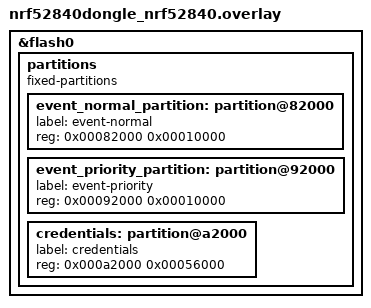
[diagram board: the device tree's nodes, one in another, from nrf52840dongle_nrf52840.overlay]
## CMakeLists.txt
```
cmake_minimum_required(VERSION 3.20.0)
find_package(Zephyr REQUIRED HINTS $ENV{ZEPHYR_BASE})
#set(ZEPHRY_MODULES modules/meta)

project(z9-lock)
include_directories(SYSTEM ../modules/meta/include)
include_directories(../z9-zephyr/ble)
target_sources(app PRIVATE src/main.cc)
target_sources(app PRIVATE src/button.c)

#target_sources(app PRIVATE ../z9-zephyr/ble/z9_ble_driver.c)
#target_sources(app PRIVATE ../z9-zephyr/ble/z9lockio_ble.cc)
target_sources(app PRIVATE ../z9-zephyr/ble/Z9Lock_status.cc)
target_sources(app PRIVATE ../z9-zephyr/ble/Eros_protocol.cc)
target_sources(app PRIVATE ../z9-zephyr/ble/Z9Crypto.cc)
target_sources(app PRIVATE ../z9-zephyr/ble/Z9Crypto_gcm_KCB.cc)
target_sources(app PRIVATE ../z9-zephyr/ble/EventDb.cc)
target_sources(app PRIVATE ../z9-zephyr/ble/Settings.cc)
target_sources(app PRIVATE ../z9-zephyr/ble/KernelBuffer.c)
target_sources(app PRIVATE ../z9-zephyr/ble/KernelCharacterBuffer.c)
target_sources(app PRIVATE ../z9-zephyr/ble/Z9LockIO_protocol.cc)
target_sources(app PRIVATE ../z9-zephyr/ble/Z9LockIO_bundleHeader.cc)
target_sources(app PRIVATE ../z9-zephyr/ble/Z9LockIO_opaqueContent.cc)
target_sources(app PRIVATE ../z9-zephyr/ble/Z9LockIO_eventControl.cc)
target_sources(app PRIVATE ../z9-zephyr/ble/Z9LockIO_keyExchange.cc)
target_sources(app PRIVATE ../z9-zephyr/ble/Z9LockIO_accessReq.cc)
target_sources(app PRIVATE ../z9-zephyr/ble/Z9LockIO_dbChange.cc)
target_sources(app PRIVATE ../z9-zephyr/ble/Z9LockIO_credAuthorization.cc)

#target_sources(app PRIVATE ../z9-zephyr/ble/DbStore.cc)
target_sources(app PRIVATE ../z9-zephyr/ble/Z9IO_Device.c)
target_sources(app PRIVATE ../z9-zephyr/ble/Z9IO_Link_Controller.cc)
# target_sources(app PRIVATE ../z9-zephyr/ble/Z9IO_Link_Remote.cc)
target_sources(app PRIVATE ../z9-zephyr/ble/ModelInfo.cc)
target_sources(app PRIVATE ../z9-zephyr/ble/Z9IO_Logic.cc)
# target_sources(app PRIVATE src/Z9Crypto.cc src/Z9Crypto_gcm_KCB.cc)
target_sources(app PRIVATE ../z9-zephyr/ble/Crc16.c)
```

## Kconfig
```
menu "Z9Lock"

config Z9_READER
    bool "Enable Reader"
    default n

config Z9_CONTROLLER
    bool "Enable Controller"
    default n
endmenu

menu "Zephyr Kernel"
source "Kconfig.zephyr"
endmenu
```

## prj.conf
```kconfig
CONFIG_CPP=y
CONFIG_STD_CPP20=y
CONFIG_LIB_CPLUSPLUS=y
CONFIG_REQUIRES_FULL_LIBCPP=y
CONFIG_EXCEPTIONS=y

CONFIG_KERNEL_BIN_NAME="z9-lock"

#CONFIG_COMPILER_SAVE_TEMPS=y
#CONFIG_COMPILER_OPT=""

CONFIG_Z9_READER=n
CONFIG_Z9_CONTROLLER=y

CONFIG_SERIAL=y
CONFIG_UART_INTERRUPT_DRIVEN=y

# configs from ECDH
# The Zephyr CMSIS emulation assumes that ticks are ms, currently
CONFIG_SYS_CLOCK_TICKS_PER_SEC=1000

#CONFIG_MAIN_STACK_SIZE=4096
#CONFIG_HEAP_MEM_POOL_SIZE=4096

CONFIG_MAIN_STACK_SIZE=4096
CONFIG_HEAP_MEM_POOL_SIZE=4096

# enable below for Zephyr BLE controller
#CONFIG_BT_LL_SW_SPLIT=y
#CONFIG_BT=y
#CONFIG_BT_PERIPHERAL=y
#CONFIG_BT_SMP=y
#CONFIG_BT_GATT_CLIENT=y


#CONFIG_BT_PERIPHERAL=y
#CONFIG_BT_DEVICE_NAME="Z9 Lock"
#CONFIG_BT_USER_PHY_UPDATE=y


CONFIG_HWINFO=y
#CONFIG_NCS_SAMPLES_DEFAULTS=y

CONFIG_LOG=n
CONFIG_LOG_BUFFER_SIZE=4096
#CONFIG_LOG_IMMEDIATE=y

# CONFIG_BT_LOG_LEVEL_DBG=n
#CONFIG_BT_DEBUG_MONITOR_UART=y
#CONFIG_UART_CONSOLE=n

# enable NVS
CONFIG_FLASH=y
CONFIG_FLASH_PAGE_LAYOUT=y
CONFIG_FCB_ALLOW_FIXED_ENDMARKER=y
CONFIG_FLASH_MAP=y
CONFIG_FCB=y
CONFIG_NVS=y
#CONFIG_NVS_LOG_LEVEL_DBG=y
CONFIG_MPU_ALLOW_FLASH_WRITE=y
CONFIG_SETTINGS=y

# Enable MBEDTLS (for Zephyr, not NFC)
CONFIG_MBEDTLS=y
CONFIG_MBEDTLS_BUILTIN=y
CONFIG_MBEDTLS_CFG_FILE="config-tls-generic.h"
CONFIG_MBEDTLS_ENTROPY_ENABLED=y
CONFIG_MBEDTLS_PSA_CRYPTO_C=y
CONFIG_MBEDTLS_ZEPHYR_ENTROPY=y
#CONFIG_MBEDTLS_HEAP_SIZE=8192
CONFIG_MBEDTLS_ECDH_C=y
CONFIG_MBEDTLS_ECP_C=y
CONFIG_MBEDTLS_ECP_DP_SECP256R1_ENABLED=y
CONFIG_MBEDTLS_HASH_SHA256_ENABLED=y
CONFIG_MBEDTLS_CIPHER_AES_ENABLED=y
CONFIG_MBEDTLS_AES_ROM_TABLES=y
CONFIG_MBEDTLS_CIPHER_GCM_ENABLED=y
CONFIG_MBEDTLS_MAC_MD5_ENABLED=y
CONFIG_MBEDTLS_MAC_SHA1_ENABLED=y
CONFIG_MBEDTLS_MAC_SHA256_ENABLED=y
CONFIG_MBEDTLS_SHA256_SMALLER=y
CONFIG_MBEDTLS_CTR_DRBG_ENABLED=y
CONFIG_MBEDTLS_CIPHER=y
CONFIG_MBEDTLS_MD=y
CONFIG_MBEDTLS_ENTROPY_ENABLED=y
CONFIG_MBEDTLS_PK_WRITE_C=y
CONFIG_MBEDTLS_PSA_CRYPTO_C=y
CONFIG_MBEDTLS_SSL_MAX_CONTENT_LEN=1500
CONFIG_MBEDTLS_INIT=y
CONFIG_MBEDTLS_ZEPHYR_ENTROPY=y

# added for ATMEL random
CONFIG_ENTROPY_GENERATOR=y
CONFIG_TEST_RANDOM_GENERATOR=y

# Enable nordic security backend and PSA APIs
# config for 52840DK
#CONFIG_PSA_CRYPTO_DRIVER_OBERON=y
#CONFIG_PSA_CRYPTO_DRIVER_CC3XX=n

#CONFIG_NRF_SECURITY=y
#CONFIG_MBEDTLS_PSA_CRYPTO_C=y

#CONFIG_MBEDTLS_ENABLE_HEAP=y

## configure PSA
#CONFIG_PSA_WANT_KEY_TYPE_ECC_KEY_PAIR=y
#CONFIG_PSA_WANT_ECC_SECP_R1_256=y
#CONFIG_PSA_WANT_ALG_ECDH=y
#CONFIG_PSA_WANT_ALG_SHA_256=y
#CONFIG_PSA_WANT_KEY_TYPE_AES=y
#CONFIG_PSA_WANT_AES_KEY_SIZE_128=y
#CONFIG_PSA_WANT_ALG_GCM=y

# For key generation
#CONFIG_PSA_WANT_GENERATE_RANDOM=y

# Enable the LBS service
#CONFIG_BT_LBS=y
#CONFIG_BT_LBS_POLL_BUTTON=y
#CONFIG_DK_LIBRARY=y

CONFIG_BT_GATT_CLIENT=y
CONFIG_BT_USER_DATA_LEN_UPDATE=y
CONFIG_BT_CTLR_DATA_LENGTH_MAX=251
CONFIG_BT_BUF_ACL_RX_SIZE=251
CONFIG_BT_BUF_ACL_TX_SIZE=251
CONFIG_BT_L2CAP_TX_MTU=420
#CONFIG_BT_HCI_ACL_FLOW_CONTROL=y
#CONFIG_BT_L2CAP_RX_MTU=420

CONFIG_SYSTEM_WORKQUEUE_STACK_SIZE=8192
```

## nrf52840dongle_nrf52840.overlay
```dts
// To get started, press Ctrl+Space (or Option+Esc) to bring up the completion menu and view the available nodes.

// You can also use the buttons in the sidebar to perform actions on nodes.
// Actions currently available include:

// * Enabling / disabling the node
// * Adding the bus to a bus
// * Removing the node
// * Connecting ADC channels

// For more help, browse the DeviceTree documentation at https://docs.zephyrproject.org/latest/guides/dts/index.html
// You can also visit the nRF DeviceTree extension documentation at https://nrfconnect.github.io/vscode-nrf-connect/devicetree/nrfdevicetree.html
/delete-node/ &slot1_partition;
&flash0 {

	partitions {
		compatible = "fixed-partitions";
		#address-cells = <1>;
		#size-cells = <1>;

		event_normal_partition: partition@82000 {
			label = "event-normal";
			reg = <0x00082000 0x00010000>;
		};
		event_priority_partition: partition@92000 {
			label = "event-priority";
			reg = <0x00092000 0x00010000>;
		};
		credentials: partition@a2000 {
			label = "credentials";
			reg = <0x000a2000 0x00056000>;
		};
    };
};
```

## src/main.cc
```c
#include "button.h"
#include "Z9Lock_status.h"
#include "EventDb.h"
#include "Settings.h"

#ifdef CONFIG_Z9_READER
#include "z9lockio_ble.h"
#endif

#include <zephyr/kernel.h>
#include <zephyr/logging/log.h>

#include <zephyr/sys/printk.h>
#include <zephyr/drivers/gpio.h>


LOG_MODULE_REGISTER(z9_ble, LOG_LEVEL_INF);
#define RUN_LED_BLINK_INTERVAL 1000

#define GREEN_LED_NODE  DT_ALIAS(led0)
#define RED_LED_NODE    DT_ALIAS(led1)
static const gpio_dt_spec green_led = GPIO_DT_SPEC_GET(GREEN_LED_NODE, gpios);
static const gpio_dt_spec red_led   = GPIO_DT_SPEC_GET(RED_LED_NODE  , gpios);

static void set_green_led(bool led)
{
        gpio_pin_set_dt(&green_led, led);
}
static void set_red_led(bool led)
{
        gpio_pin_set_dt(&red_led, led);
}
static int init_leds()
{
        int err;
        err = gpio_is_ready_dt(&green_led);
        if (err < 0) return err;
     	err = gpio_pin_configure_dt(&green_led, GPIO_OUTPUT_ACTIVE);
        if (err < 0) return err;
        err = gpio_is_ready_dt(&red_led);
        if (err < 0) return err;
     	err = gpio_pin_configure_dt(&red_led, GPIO_OUTPUT_ACTIVE);
        if (err < 0) return err;
        set_green_led(0);
        set_red_led(0);
        return 0;
}

static void pairing_expired(struct k_work *work)
{
        printk("%s: expired\n", __func__);
        z9lock_status.set_mode(LockStatusMode::CONSTRUCTION);
}

static void perform_reset(struct k_work *work)
{
        printk("%s: expired\n", __func__);
        nvm_settings_reset();           // clear flash
        __NVIC_SystemReset();
}

K_WORK_DELAYABLE_DEFINE(pairing_timer, pairing_expired);
K_WORK_DELAYABLE_DEFINE(reset_timer  , perform_reset);

bool privacy_state;
static void button_changed(button_evt evt)
{
        auto&& lock = z9lock_status;
                
        bool is_pressed = evt == BUTTON_EVT_PRESSED;
        printk("red: is_pressed: %d\n", is_pressed);

        if (is_pressed)
                k_work_schedule(&reset_timer, K_SECONDS(10));
        else 
        {
                k_work_cancel_delayable(&reset_timer);

                // if in paired, then it's the priv button
                if (lock.mode == LockStatusMode::NORMAL)
                {
                        privacy_state ^= 1; //bool(button_state & RED_BUTTON);
                        set_red_led(privacy_state);
                }
                else
                {
                        k_work_schedule(&pairing_timer, K_SECONDS(30));
                        lock.set_mode(LockStatusMode::PAIRING);
                }
        }

        auto lock_mode = static_cast<uint8_t>(lock.mode);
        printk("%s: MODE=%d, PRIV=%d\n", __func__, lock_mode, privacy_state);
}


int main()
{
        int err;

        printk("Starting Z9Lock BLE Test Fixture\n");
        psa_crypto_init();              // XXX
 

#ifdef CONFIG_Z9_READER 
        // start the Z9 BLE stack
        printk("Initializing Bluetooth\n");
        z9lock_ble_init();
#endif

#ifdef CONFIG_Z9_CONTROLLER
        // LEDs & buttons on READER
        err = init_leds();
        if (err) {
                printk("LEDs init failed (err %d)\n", err);
                return err;
        }

        err = button_init(button_changed);
        if (err) {
                printk("Button init failed (err %d)\n", err);
                return err;
        }
        
        nvm_settings_init();           // read settings: retrive keys & set mode

        // startup complete -- generate an event
        LockEventDb::instance().save(EVT(LockEvtCode_STARTUP));

        // if in construction or pairing mode, blink LED 
        uint8_t blink_status = 0;
        for (;;)
        {
                auto&& lock = z9lock_status;

                auto led = false;
                ++blink_status;
                switch (lock.mode)
                {
                        case LockStatusMode::PAIRING:
                                blink_status %= 5;
                                // FALLSTHRU
                        case LockStatusMode::CONSTRUCTION:
                                led = blink_status & 1;
                                set_green_led(led);
                                break;
                        default:
                                set_green_led(0);
                                return 0;
                }

                k_sleep(K_MSEC(RUN_LED_BLINK_INTERVAL/2));
        }
 #endif       
        // NOTREACHED
}
```

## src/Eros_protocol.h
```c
#include <cinttypes>
#include <zephyr/bluetooth/conn.h>

#include "z9lockio_ble.h"

#define NVS_PARTITION		storage_partition
#define NVS_PARTITION_DEVICE	FIXED_PARTITION_DEVICE(NVS_PARTITION)
#define NVS_PARTITION_OFFSET	FIXED_PARTITION_OFFSET(NVS_PARTITION)

// includes for NVS
#include <zephyr/device.h>
#include <string.h>
#include <zephyr/drivers/flash.h>
#include <zephyr/storage/flash_map.h>
#include <zephyr/fs/nvs.h>

#pragma once

void set_lock_mode();
void lock_mode_reset();

/*
 * Leaf BLE messaging protocol structure.
 */

enum struct leaf_tag_t : uint8_t {
    ACK_NACK = 0x00,
    ECIES_REQ = 0x09,
    ECIES_RSP = 0x0a,
    PASSTHRU  = 0x0b,
}; 

struct _leaf_ble_msg_t
{
    uint8_t     start;      // start sequence byte 0x82 or 0xC2
    leaf_tag_t  tag;        // msg tag
    uint16_t    length;     // 2 byte msg length, network order

    // these fields are included in the length and encrypted for cipher msgs
    uint8_t     sequence;  // 1 byte rotating sequence
    uint8_t     data[400]; // msg payload
};

enum struct leaf_ble_status_t : uint8_t {
    OK   = 0x00,
    ERR  = 0x01,
    AUTH = 0x02,
};

// also serves as message length
enum struct ecies_type_: uint8_t {
    ECIES_ID = 8,           // request public ID
    ECIES_KEY = 65,         // the public key
    ECIES_NONCE = 16,       // generated value for one time use
};


/*
 * Passthrough message type structure.
 */
struct passthrough_value_t
{
    uint8_t     target;     // entity the payload is targeted for
    uint8_t     index;      // fragment index: zero basesd
    uint8_t     total;      // total number of fragments in communication
    uint8_t     length;     // big endian fragment length
    uint8_t     data[395];  // fragment data
};

// IDs 0-128 for commands, IDs 129-255 for responses
// NB: uneven number ranges in original
enum struct target_id_t : uint8_t {
    MODULE = 0,
    HOST,
    CLIENT = 129,
    SERVICE,
};

void eros_ble_recv(bt_conn *conn, const void *buf, uint16_t buf_len);
```

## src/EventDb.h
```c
/*
 * Events are stored in a pair of circular buffers: one for priority events and one for normal events.
 * The zephyr facility: File-Circular-Buffers is used to facilitate the storage
 * 
 * Provide a single "store event" interface which examines the Event to determine the file
*/

#pragma once

#include "Z9LockIOProtocol_Current.h"

#include <zephyr/device.h>
#include <zephyr/drivers/flash.h>
#include <zephyr/storage/flash_map.h>
#include <zephyr/fs/fcb.h>
#include <string.h>
#include <cstdint>
#include <functional>
#include <utility>
#include <time.h>

// macro to create EVENT

// TODO: add args to set flags other than true
#define  EVT(code, MODS...)  LockEvt{ .evtCode=code }
#define PEVT(code, MODS...)  LockEvt{ .evtCode=code, {.priority=true}}


// Declare the FileSystem Names
#define FS_NORMAL       event_normal
#define FS_PRIORITY     event_priority

using namespace z9;

// Declare Data-type stored in the Event Circular buffer
struct LockEventFsItem
{
    // to be written: set time, possibly add header
    LockEventFsItem(LockEvt const& evt, uint8_t id, const void *content, uint16_t contentLength);

    // convert retrieved item to object
    LockEventFsItem(uint8_t *data, uint16_t bytesRead);

    // get pointer + count for write
    uint16_t getRaw(uint8_t *data, uint16_t max) const;

    bool isDeleted() const { return evt.evtCode == 0; }
    void serialize(std::function<void(uint8_t)> const& writer) const;

    // utilities
    bool priority() const { return evt.modifiers.priority; }
    auto evtCode () const { return evt.evtCode;            }
    
    enum class EventCompare { Before, Equal, After }; 
    EventCompare test(LockEvtIdentifierRange const& id) const;

    bool matches(LockEvtIdentifier const& id) const;
    void doDelete(fcb_entry_ctx *loc_ctx);
//private:
    LockEvt evt;
    uint8_t id;
    const void *content;
    uint16_t contentLength;

};

// Declare the File System
struct LockEventFs
{
    // XXX doClear should be false for production
    LockEventFs(int fixed_area_id, std::size_t sizeBytes, bool doClear = true)
    {
        uint32_t cnt = sizeBytes / 4096;
        auto p  = new flash_sector[sizeBytes/4096];
        auto rc = flash_area_get_sectors(fixed_area_id, &cnt, p);
        file.f_sector_cnt = cnt;
        file.f_sectors    = p;
        if (rc < 0)
            printk("%s: flash_area_get_sectors failed: %d\n", __func__, rc);
        else if ((rc = fcb_init(fixed_area_id, &file)))
            printk("%s: fcb_init failed: %d\n", __func__, rc);
        else
            printk("%s: fcb_init complete\n", __func__);

        if (doClear)
            fcb_clear(&file);
    }

    // put item in FS directly
    void write(LockEventFsItem const& evt);

    // walk thru FCB items to report or select for delete
    int walk(fcb_walk_cb cb, void *cb_arg = {}, flash_sector *sector = {})
    {
        return fcb_walk(&file, sector, cb, cb_arg);
    }

    // recycle oldest sector
    void rotate() { fcb_rotate(&file); }

    bool isEmpty() { return fcb_is_empty(&file); }
private:
    fcb file {};
};

// Declare the Event Database interface class
struct LockEventDb 
{
    // allow content to be passed as "type"
    template <typename T = LockEvtContent_None>
    void save(LockEvt const& evt, T const& content = {}) const
    {
        return save(evt, T::DISCRIMINATOR, static_cast<const void *>(&content), sizeof(T));
    }

    // Z9LockIO Protocol support
    void consume(bool priority, LockEvtIdentifier const& from, LockEvtIdentifier const& to) const;
    uint8_t extract(bool priority, uint8_t max, std::function<void(uint8_t)> const& writer) const;

    void dump() const;

    // test if event buffers(s) are empty
    bool isEmpty() const { return getFs(false).isEmpty() && getFs(true).isEmpty(); }

    static auto& instance()
    {
        static LockEventDb _;
        return _;
    }

private:
    // TODO: errors (or let Throw handle it)
    // save an event. length is of variable content only
    // NB: event times are overwritten to ensure asending order
    void save(LockEvt const& evt, uint8_t id, const void *content_p, uint16_t contentLength) const;

    // NB: put `LockEventFs` in static methods so that ctors will not run at startup
    // NB: local static's are initialized first time control passes thru
    static auto& priorityFs()
    {
        static LockEventFs fs(FIXED_PARTITION_ID(event_priority_partition),
                              FIXED_PARTITION_SIZE(event_priority_partition));
        return fs;
    }
    static auto& normalFs()
    {
        static LockEventFs fs(FIXED_PARTITION_ID(event_normal_partition),
                              FIXED_PARTITION_SIZE(event_normal_partition));
        return fs;
    }
    LockEventFs& getFs(bool priority) const
    {
        return priority ? priorityFs() : normalFs();
    }
};
```

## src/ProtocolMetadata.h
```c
#include <meta/meta.hpp>
#include "kas_string.h"
#include "init_from_list.h"


#pragma once

#define Z9_STRING KAS_STRING

namespace z9{}
namespace z9::protocol
{
   using namespace meta;

// macro to hold structure member metadata
#define Z9_MEMBER(s_type, wire_size, name, ...) \
       list<int_<wire_size>                        \
          , int_<offsetof(s_type, name)>           \
          , int_<sizeof(std::declval<s_type>().name)> \
          , decltype(std::declval<s_type>().name)  \
          , Z9_STRING(#name)>

#define Z9_MEMBER_NONE() \
 list<int_<0>, int_<0>, int_<0>, uint8_t, Z9_STRING("*none*")>

// expand to arrays:
// constexpr auto names[] = {
//      [NAME ## _ ## _VALUE] = #NAME,
//      ... for each VALUE ...
//  };

#define Z9_ENUM(NAME, VALUES...)  list<NAME, Z9_STRING(#NAME), Z9_STRING(#VALUES),...>
}
```

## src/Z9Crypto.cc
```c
#include "Z9Crypto.h"
#include <zephyr/logging/log.h>
#include <zephyr/kernel.h>      // printk

#include <cstring>
#include <cstdint>

LOG_MODULE_REGISTER(Z9Crypto, LOG_LEVEL_DBG);

uint8_t raw_lock_public_key[33];
uint8_t raw_application_key[16];

// create GSM key from raw bytes
psa_status_t Z9Crypto_gcmSetKey(psa_key_id_t& handle, const uint8_t *keyBytes, uint16_t numKeyBytes)
{
    psa_status_t status;
    psa_key_attributes_t attributes = PSA_KEY_ATTRIBUTES_INIT;

    status = psa_crypto_init();
    if (status != PSA_SUCCESS)
    {
        LOG_ERR("%s: psa_init_failed: %d", __func__, status);
        return status;
    }

   /* Set key attributes */
    psa_set_key_usage_flags(&attributes, PSA_KEY_USAGE_ENCRYPT | PSA_KEY_USAGE_DECRYPT);
    psa_set_key_lifetime(&attributes, PSA_KEY_LIFETIME_VOLATILE);
    psa_set_key_algorithm(&attributes, PSA_ALG_GCM);
    psa_set_key_type(&attributes, PSA_KEY_TYPE_AES);
    psa_set_key_bits(&attributes, numKeyBytes * 8);

    /* Import the key */
    status = psa_import_key(&attributes, keyBytes, numKeyBytes, &handle);
    if (status != PSA_SUCCESS) {
        LOG_ERR("%s: Failed to import key: %d", __func__, status);
        return status;
    }

    /* Free the attributes */
    psa_reset_key_attributes(&attributes);
    return PSA_SUCCESS;
}

void Z9Crypto_destroyKey(psa_key_id_t& handle)
{
    /* Destroy the key */
    psa_destroy_key(handle);

    mbedtls_psa_crypto_free();
    handle = {};
}

// generate a 128 bit random number
uint8_t *Z9Crypto_random()
{
    static uint8_t random[16];
    psa_status_t status = psa_generate_random(random, sizeof(random));
    if (!status)
        return random;
    return {};
}

// single function entrypoint: assume 12-byte nonce
// uses multi-part PSA interface
psa_status_t Z9Crypto_gcm_encrypt(psa_key_id_t const& key,
                          const uint8_t *nonce,
                          const uint8_t *aad,
                          size_t aad_length,
                          uint8_t *text,
                          size_t  text_length,
                          uint8_t *tag,
                          size_t tag_length)
{
    psa_status_t status;
    size_t written;
    uint8_t temp[text_length], *output = temp;

    psa_aead_operation_t operation = PSA_AEAD_OPERATION_INIT;
    psa_aead_encrypt_setup(&operation, key, PSA_ALG_GCM);
    psa_aead_set_lengths(&operation, aad_length, text_length);
    psa_aead_set_nonce(&operation, nonce, 12);

    if (aad_length)
        psa_aead_update_ad(&operation, aad, aad_length);
    if (text_length)
    {
        psa_aead_update(&operation, text, text_length,
                                    output, text_length, &written);
        // record bytes written
        output      += written;
    }
    status = psa_aead_finish(&operation, output, text_length, &written, tag, tag_length, &tag_length);
    std::memcpy(text, temp, text_length);
    return status;
}

void print_hex(const char *fn, const char *pfx, uint8_t const *data, std::size_t len)
{
    printk("%s: %s (%d bytes): ", fn, pfx, len);
    while(len--)
        printk("%02x", *data++);
    printk("\n");
}


// decrypt block of cipher text
psa_status_t Z9Crypto_gcm_decrypt(psa_key_id_t const& key,
                          const uint8_t *nonce,
                          const uint8_t *aad,
                          size_t aad_length,
                          uint8_t *text,
                          size_t  text_length,
                          uint8_t *tag,
                          size_t tag_length)
{
    psa_status_t status;
    size_t written = {};
    uint8_t temp[text_length], *output = temp;


    psa_aead_operation_t operation = PSA_AEAD_OPERATION_INIT;
    printk("%s: key = %d (%08x)\n", __func__, key, key);
    //print_hex(__func__, "input", text, text_length);
    //print_hex(__func__, "iv ", nonce, 12);
    //print_hex(__func__, "tag", tag, 16);
    //print_hex(__func__, "in ", text, text_length);

    status = psa_aead_decrypt_setup(&operation, key, PSA_ALG_GCM);
        if (status)
        {
            printk("%s: error: psa_aead_decrypt_setup: %d\n", __func__, status);
        }
    status = psa_aead_set_lengths(&operation, aad_length, text_length);
        if (status)
        {
            printk("%s: error: psa_aead_set_lengths: %d\n", __func__, status);
        }
    status = psa_aead_set_nonce(&operation, nonce, 12);
        if (status)
        {
            printk("%s: error: psa_aead_set_nonce: %d\n", __func__, status);
        }

    if (aad_length)
    {
        psa_aead_update_ad(&operation, aad, aad_length);
    }
    if (text_length)
    {
        status = psa_aead_update(&operation, text , text_length,
                                    output, text_length, &written);
        if (status)
        {
            printk("%s: error: psa_aead_update: %d\n", __func__, status);
        }
        output += written;
    }
    //print_hex(__func__, "raw", temp, output-temp);
    status = psa_aead_verify(&operation, output, text_length, &written, tag, tag_length);
    output += written;
    print_hex(__func__, "out", temp, output-temp);
    std::memcpy(text, temp, text_length);
    return status;
}
```

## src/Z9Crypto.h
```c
//
//  GcmCrypto.h
//

// Generic interface to encrypt, decrypt, and hash using the Galois/Counter Mode of AES
//
// This module also allows for GCM encryption of data which provided in discontigous
// chunks of data, divided by time and/or space. The module is designed take the
// multiple chucks of data, collect it into properly page-aligned 128-bit blocks, and
// perform the proper AES opertions on those blocks. 
//
// This module virtualizes the AES encryption hardware to provide several virtual
// encryption channels. Each channel has it's own keys and state and run independently.
// Thus a multi-packet download stream can be interrupted by link or NOC stream w/o
// interference.
//
// The GcmCrypto module manages passing instructions and data to the hardware engine.
// The hardware engine requires 32-bit alignment for all data, and keys. The GcmCrypto
// module provides this alignment. It will also buffer and zero pad AAD and DATA streams
// as required.
//
// Each virtual GCM channel is identified by an `enum CrytpoStream`.
// Before data can be run thru a channel, it must have it's KEY set and specify a
// return route for notifications.
//
// After initialization, each GCM channel expects a sequence of messages in the following order:
//
// specify IV, the aad length, and the text length. Only 96-bit IVs are supported
//z9_error_t gcmCrypto_doNewMessage(GcmCrypto *gcm, const uint8_t *iv, uint32_t aadLength, uint32_t textLength);
//
// process block of aad data
//z9_error_t gcmCrypto_queueProcessAad(GcmCrypto *gcm, const uint8_t *aadPtr, uint32_t bytes);
//
// encrypt block of plain text
//z9_error_t gcmCrypto_queueEncrypt(GcmCrypto *gcm, const uint8_t *plain, uint8_t *out, uint32_t bytes);
//
// decrypt block of cipher text
//z9_error_t gcmCrypto_queueDecrypt(GcmCrypto *gcm, const uint8_t *cipher, uint8_t *out, uint32_t bytes);
//
// generate the TAG (up to 16 bytes of tag can be generated)
//z9_error_t gcmCrypto_queueGenerateTag(GcmCrypto *gcm, uint8_t *tag, uint16_t tagBytes);
//
// The plain & cipher text do not need to be multiples of the 16-byte AES block, nor to they
// have any alignment requirements. The input & output can be the same for encrypt/decrypt in
// place. The output can be omitted (NULL) for validation of tag.


#pragma once

#include <psa/crypto.h>
#include <psa/crypto_extra.h>
#include <cstdint>

using z9_error_t = const char *;

// create GSM key from raw bytes
psa_status_t Z9Crypto_gcmSetKey(psa_key_id_t& handle, const uint8_t *keyBytes, uint16_t numKeyBytes);



// remove key when complete
void Z9Crypto_destroyKey(psa_key_id_t& handle);

// generate a 128 bit random number
uint8_t *Z9Crypto_random();

// encrypt / decrypt in place
psa_status_t Z9Crypto_gcm_encrypt(psa_key_id_t const& key,
                          const uint8_t *nonce,
                          const uint8_t *aad,
                          size_t aad_length,
                          uint8_t *text,
                          size_t  text_length,
                          uint8_t *tag,
                          size_t  tag_length);

psa_status_t Z9Crypto_gcm_decrypt(psa_key_id_t const& key,
                          const uint8_t *nonce,
                          const uint8_t *aad,
                          size_t aad_length,
                          uint8_t *text,
                          size_t  text_length,
                          uint8_t *tag,
                          size_t  tag_length);

// XXX to be removed
extern uint8_t raw_lock_public_key[33];
extern uint8_t raw_application_key[16];
```

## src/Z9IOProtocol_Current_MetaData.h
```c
// Copyright (C) 2011-Infinity Z9 Security. All rights reserved.

// Z9IOProtocol_Current_MetaData.h

#include "ProtocolMetadata.h"
#include "Z9IOProtocol_Current.h"

namespace z9::drivers::z9io::protocol
{

using meta::list;

using Z9_TYPES = list<
	list<PacketContent, Z9_STRING("PacketContent"),
		list<
			Z9_MEMBER(PacketContent, 1, contentType, int8_t)
			// TODO: variable   |            |            | discriminator-specific content
		>
	>,

	list<RawRead, Z9_STRING("RawRead"),
		list<
			Z9_MEMBER(RawRead, 1, readerIndex, int8_t),
			Z9_MEMBER(RawRead, 1, trimBitsInLastByte, int8_t),
			Z9_MEMBER(RawRead, 33, bytes, variableArray<32, int8_t, int8_t>)
		>
	>,

	list<RawKey, Z9_STRING("RawKey"),
		list<
			Z9_MEMBER(RawKey, 1, keypadIndex, int8_t),
			Z9_MEMBER(RawKey, 1, key, int8_t)
		>
	>,

	list<DigitalRead, Z9_STRING("DigitalRead"),
		list<
			Z9_MEMBER(DigitalRead, 1, inputIndex, int8_t),
			Z9_MEMBER(DigitalRead, 1, value, bool),
			Z9_MEMBER(DigitalRead, 1, active, bool)
		>
	>,

	list<TemperatureRead, Z9_STRING("TemperatureRead"),
		list<
			Z9_MEMBER(TemperatureRead, 1, deviceIndex, int8_t)
			// TODO: 8 elements (8 bytes) | `deviceAddress` | int8_t     | ,
			Z9_MEMBER(TemperatureRead, 4, tempC, float),
			Z9_MEMBER(TemperatureRead, 4, humidity, float)
		>
	>,

	list<BoardInfo, Z9_STRING("BoardInfo"),
		list<
			Z9_MEMBER(BoardInfo, 1, protocolVersionMajor, int8_t),
			Z9_MEMBER(BoardInfo, 1, protocolVersionMinor, int8_t),
			Z9_MEMBER(BoardInfo, 2, model, int16_t),
			Z9_MEMBER(BoardInfo, 1, firmwareVersionMajor, int8_t),
			Z9_MEMBER(BoardInfo, 1, firmwareVersionMinor, int8_t),
			Z9_MEMBER(BoardInfo, 1, encryptionEnabled, bool),
			Z9_MEMBER(BoardInfo, 8, serialNumber, int64_t),
			Z9_MEMBER(BoardInfo, 1, spare, int8_t),
			Z9_MEMBER(BoardInfo, 2, webServerPort, int16_t),
			Z9_MEMBER(BoardInfo, 2, protocolServerPort, int16_t),
			Z9_MEMBER(BoardInfo, 1, mega, bool),
			Z9_MEMBER(BoardInfo, 1, enableSD, bool),
			Z9_MEMBER(BoardInfo, 1, enableEthernet, bool),
			Z9_MEMBER(BoardInfo, 1, enableSystemLED, bool),
			Z9_MEMBER(BoardInfo, 1, enableDigitalIn, bool),
			Z9_MEMBER(BoardInfo, 1, enableDigitalOut, bool),
			Z9_MEMBER(BoardInfo, 1, enableAnalogIn, bool),
			Z9_MEMBER(BoardInfo, 1, enableData01, bool),
			Z9_MEMBER(BoardInfo, 1, enableRfid, bool),
			Z9_MEMBER(BoardInfo, 1, enableLCD, bool),
			Z9_MEMBER(BoardInfo, 1, enableKeypad, bool),
			Z9_MEMBER(BoardInfo, 1, enableDallasTemperature, bool),
			Z9_MEMBER(BoardInfo, 1, enableSHTXTemperature, bool)
		>
	>,

	list<AnalogRead, Z9_STRING("AnalogRead"),
		list<
			Z9_MEMBER(AnalogRead, 1, inputIndex, int8_t),
			Z9_MEMBER(AnalogRead, 2, value, int16_t),
			Z9_MEMBER(AnalogRead, 1, active, int8_t)
		>
	>,

	list<FileContents, Z9_STRING("FileContents"),
		list<
			Z9_MEMBER(FileContents, 1, fileId, int8_t),
			Z9_MEMBER(FileContents, 4, offset, int32_t),
			Z9_MEMBER(FileContents, 1, eof, bool),
			Z9_MEMBER(FileContents, 1, exception, int8_t),
			Z9_MEMBER(FileContents, 1026, bytes, variableArray<1024, int16_t, int8_t>)
		>
	>,

	list<BoardStatus, Z9_STRING("BoardStatus"),
		list<
			Z9_MEMBER(BoardStatus, 4, millis, int32_t),
			Z9_MEMBER(BoardStatus, 2, memoryAvailable, int16_t),
			Z9_MEMBER(BoardStatus, 1, helloReceived, bool),
			Z9_MEMBER(BoardStatus, 1, protocolConnectionType, int8_t),
			Z9_MEMBER(BoardStatus, 4, numSerialProtocolPacketsRead, int32_t),
			Z9_MEMBER(BoardStatus, 4, numSerialProtocolPacketsWritten, int32_t),
			Z9_MEMBER(BoardStatus, 4, numNetworkProtocolPacketsRead, int32_t),
			Z9_MEMBER(BoardStatus, 4, numNetworkProtocolPacketsWritten, int32_t),
			Z9_MEMBER(BoardStatus, 4, numSerialProtocolInputErrors, int32_t),
			Z9_MEMBER(BoardStatus, 2, lastSerialProtocolInputError, int16_t),
			Z9_MEMBER(BoardStatus, 4, numSerialProtocolOutputErrors, int32_t),
			Z9_MEMBER(BoardStatus, 2, lastSerialProtocolOutputError, int16_t),
			Z9_MEMBER(BoardStatus, 4, numNetworkProtocolInputErrors, int32_t),
			Z9_MEMBER(BoardStatus, 2, lastNetworkProtocolInputError, int16_t),
			Z9_MEMBER(BoardStatus, 4, numNetworkProtocolOutputErrors, int32_t),
			Z9_MEMBER(BoardStatus, 2, lastNetworkProtocolOutputError, int16_t),
			Z9_MEMBER(BoardStatus, 4, numSdErrors, int32_t),
			Z9_MEMBER(BoardStatus, 2, lastSdError, int16_t)
		>
	>,

	list<Pong, Z9_STRING("Pong"),
		list<
		>
	>,

	list<Ack, Z9_STRING("Ack"),
		list<
			Z9_MEMBER(Ack, 1, spare, int8_t),
			Z9_MEMBER(Ack, 1, responseToSeqno, int8_t)
		>
	>,

	list<Nak, Z9_STRING("Nak"),
		list<
			Z9_MEMBER(Nak, 1, spare, int8_t),
			Z9_MEMBER(Nak, 1, responseToSeqno, int8_t),
			Z9_MEMBER(Nak, 1, reason, int8_t)
		>
	>,

	list<RawKeys, Z9_STRING("RawKeys"),
		list<
			Z9_MEMBER(RawKeys, 1, keypadIndex, int8_t),
			Z9_MEMBER(RawKeys, 33, keys, variableArray<32, int8_t, int8_t>)
		>
	>,

	list<UserIdRead, Z9_STRING("UserIdRead"),
		list<
			Z9_MEMBER(UserIdRead, 1, readerIndex, int8_t),
			Z9_MEMBER(UserIdRead, 33, userIdChars, variableArray<32, int8_t, int8_t>)
		>
	>,

	list<ReaderStatus, Z9_STRING("ReaderStatus"),
		list<
			Z9_MEMBER(ReaderStatus, 1, readerIndex, int8_t),
			Z9_MEMBER(ReaderStatus, 1, offline, bool),
			Z9_MEMBER(ReaderStatus, 1, tamper, bool),
			Z9_MEMBER(ReaderStatus, 1, power, bool)
		>
	>,

	list<FileAvailable, Z9_STRING("FileAvailable"),
		list<
			Z9_MEMBER(FileAvailable, 1, fileId, int8_t),
			Z9_MEMBER(FileAvailable, 4, fileLength, int32_t)
		>
	>,

	list<ProcessFile, Z9_STRING("ProcessFile"),
		list<
			Z9_MEMBER(ProcessFile, 1, fileId, int8_t)
		>
	>,

	list<Ping, Z9_STRING("Ping"),
		list<
		>
	>,

	list<BoardStatusQuery, Z9_STRING("BoardStatusQuery"),
		list<
		>
	>,

	list<Config, Z9_STRING("Config"),
		list<
			Z9_MEMBER(Config, 1, enableSystemLED, int8_t),
			Z9_MEMBER(Config, 4, enableDigitalIn, int32_t),
			Z9_MEMBER(Config, 4, enableDigitalOut, int32_t),
			Z9_MEMBER(Config, 2, enableAnalogIn, int16_t),
			Z9_MEMBER(Config, 1, enableData01, int8_t),
			Z9_MEMBER(Config, 1, enableRfid, int8_t),
			Z9_MEMBER(Config, 1, enableLCD, int8_t),
			Z9_MEMBER(Config, 1, enableDallasTemperature, int8_t),
			Z9_MEMBER(Config, 1, enableSHTXTemperature, int8_t),
			Z9_MEMBER(Config, 1, enableKeypad, int8_t)
		>
	>,

	list<FileQuery, Z9_STRING("FileQuery"),
		list<
			Z9_MEMBER(FileQuery, 1, fileId, int8_t),
			Z9_MEMBER(FileQuery, 4, offset, int32_t)
		>
	>,

	list<Hello, Z9_STRING("Hello"),
		list<
			Z9_MEMBER(Hello, 1, protocolVersionMajor, int8_t),
			Z9_MEMBER(Hello, 1, protocolVersionMinor, int8_t),
			Z9_MEMBER(Hello, 1, multidrop, bool),
			Z9_MEMBER(Hello, 1, encryptionEnabled, bool)
		>
	>,

	list<SerialWrite, Z9_STRING("SerialWrite"),
		list<
			Z9_MEMBER(SerialWrite, 1, portIndex, int8_t),
			Z9_MEMBER(SerialWrite, 49, bytes, variableArray<48, int8_t, int8_t>)
		>
	>,

	list<DisplayWrite, Z9_STRING("DisplayWrite"),
		list<
			Z9_MEMBER(DisplayWrite, 1, portIndex, int8_t),
			Z9_MEMBER(DisplayWrite, 49, bytes, variableArray<48, int8_t, int8_t>)
		>
	>,

	list<AnalogInConfig, Z9_STRING("AnalogInConfig"),
		list<
			Z9_MEMBER(AnalogInConfig, 1, inputIndex, int8_t),
			Z9_MEMBER(AnalogInConfig, 1, enabled, bool),
			Z9_MEMBER(AnalogInConfig, 1, invert, bool),
			Z9_MEMBER(AnalogInConfig, 1, reportAllData, bool),
			Z9_MEMBER(AnalogInConfig, 2, debounce, int16_t),
			Z9_MEMBER(AnalogInConfig, 2, loStart, int16_t),
			Z9_MEMBER(AnalogInConfig, 2, loStop, int16_t),
			Z9_MEMBER(AnalogInConfig, 2, hiStart, int16_t),
			Z9_MEMBER(AnalogInConfig, 2, hiStop, int16_t),
			Z9_MEMBER(AnalogInConfig, 2, tolerance, int16_t),
			Z9_MEMBER(AnalogInConfig, 2, pollInterval, int16_t)
		>
	>,

	list<DigitalInConfig, Z9_STRING("DigitalInConfig"),
		list<
			Z9_MEMBER(DigitalInConfig, 1, inputIndex, int8_t),
			Z9_MEMBER(DigitalInConfig, 1, enabled, bool),
			Z9_MEMBER(DigitalInConfig, 1, invert, bool),
			Z9_MEMBER(DigitalInConfig, 1, reportAllData, bool),
			Z9_MEMBER(DigitalInConfig, 1, enablePullup, bool),
			Z9_MEMBER(DigitalInConfig, 2, debounce, int16_t)
		>
	>,

	list<DigitalWrite, Z9_STRING("DigitalWrite"),
		list<
			Z9_MEMBER(DigitalWrite, 1, outputIndex, int8_t),
			Z9_MEMBER(DigitalWrite, 1, value, int8_t),
			Z9_MEMBER(DigitalWrite, 2, duration, int16_t)
		>
	>,

	list<RawWrite, Z9_STRING("RawWrite"),
		list<
			Z9_MEMBER(RawWrite, 1, readerIndex, int8_t),
			Z9_MEMBER(RawWrite, 1, trimBitsInLastByte, int8_t),
			Z9_MEMBER(RawWrite, 33, bytes, variableArray<32, int8_t, int8_t>)
		>
	>,

	list<ReaderState, Z9_STRING("ReaderState"),
		list<
			Z9_MEMBER(ReaderState, 1, readerIndex, int8_t),
			Z9_MEMBER(ReaderState, 1, doorModeType, int8_t),
			Z9_MEMBER(ReaderState, 1, stateType, int8_t),
			Z9_MEMBER(ReaderState, 4, stateTypeSeqNo, int32_t),
			Z9_MEMBER(ReaderState, 33, userIdChars, variableArray<32, int8_t, int8_t>),
			Z9_MEMBER(ReaderState, 1, credUnidPresent, bool),
			Z9_MEMBER(ReaderState, 4, credUnid, int32_t),
			Z9_MEMBER(ReaderState, 1, credHolderUnidPresent, bool),
			Z9_MEMBER(ReaderState, 4, credHolderUnid, int32_t)
		>
	>,

	list<Poll, Z9_STRING("Poll"),
		list<
		>
	>,

	list<HostInfo, Z9_STRING("HostInfo"),
		list<
			Z9_MEMBER(HostInfo, 2, model, uint16_t),
			Z9_MEMBER(HostInfo, 1, firmwareVersionMajor, uint8_t),
			Z9_MEMBER(HostInfo, 1, firmwareVersionMinor, uint8_t),
			Z9_MEMBER(HostInfo, 8, serialNumber, uint64_t)
		>
	>,

	list<HostStatus, Z9_STRING("HostStatus"),
		list<
			Z9_MEMBER(HostStatus, 1, pairingState, HostPairingState),
			Z9_MEMBER(HostStatus, 1, tamper, bool),
			Z9_MEMBER(HostStatus, 1, lowBattery, bool),
			Z9_MEMBER(HostStatus, 1, syncRequested, bool)
		>
	>,

	list<EncryptedContent, Z9_STRING("EncryptedContent"),
		list<
			Z9_MEMBER(EncryptedContent, 1026, bytes, variableArray<1024, int16_t, int8_t>)
		>
	>,

	list<EncryptionKeyExchange, Z9_STRING("EncryptionKeyExchange"),
		list<
			Z9_MEMBER(EncryptionKeyExchange, 1, type, EncryptionKeyExchangeType),
			Z9_MEMBER(EncryptionKeyExchange, 17, bytes, variableArray<16, int8_t, int8_t>)
		>
	>,

	list<ApplicationEncryptionKeyExchange, Z9_STRING("ApplicationEncryptionKeyExchange"),
		list<
			Z9_MEMBER(ApplicationEncryptionKeyExchange, 1, type, ApplicationEncryptionKeyExchangeType),
			Z9_MEMBER(ApplicationEncryptionKeyExchange, 66, bytes, variableArray<65, int8_t, int8_t>)
		>
	>,

	list<Packet, Z9_STRING("Packet"),
		list<
			Z9_MEMBER(Packet, 1, headerByte, int8_t),
			Z9_MEMBER(Packet, 2, bytecount, int16_t),
			Z9_MEMBER(Packet, 1, address, int8_t),
			Z9_MEMBER(Packet, 1, seqno, int8_t)
			// TODO: 1 to 1034 bytes | `content`  | PacketContent | discriminator-based structure,
			Z9_MEMBER(Packet, 2, crc16, int16_t)
		>
	>
>;

}
```

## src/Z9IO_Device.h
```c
/**
 * @file
 * @brief API for Z9IO Physical Layer 
 *
 */


#pragma once

#include "KernelCharacterBuffer.h"

#include <zephyr/kernel.h>
#include <zephyr/device.h>
#include <stddef.h>

#ifdef __cplusplus
extern "C" {
#endif

// XXX move to KConfig
#define CONFIG_Z9IO_INSTANCES   1
#define CONFIG_Z9IO_LOG_LEVEL   3

// forward declare implementation data
struct z9io_device;

/**
 * @brief Set Z9IO Link Controller callback pointers
 *
 * 
 */
struct z9io_device *
	Z9IO_device_init(unsigned ordinal, const struct device *dev);

/**
 * @brief Function to begin KCB transmission
 *
 * KCB does not include the initial FLAG nor trailing 16-bit CRC.
 * The calculated CRC is passed separately.
 * 
 * The Driver exec `tx_return` when transmission is complete
 */
void Z9IO_device_xmit(struct z9io_device *, kcb_t *, uint16_t crc, struct k_work *tx_return);

/**
 * @brief Function to enable Z9IO receiver
 *
 * The receiver performs the following:
 * 1) It starts timer for completion
 * 2) It scans for Z9IO_FLAG, absorbing characters until received
 * 3) It scans for 16-bit length (network order) and places in KCB
 * 4) It receives `length` additional characters, less FLAG, length and CRC (5 characters)
 * 5) It receives two CRC characters at `crc *`
 * 6) It stops timer and execs `rx_return`
 * 
 * If the timer expires, a `Z9IO_FLAG` is prepended to the buffer indicating error
 * If a receive error occurs (eg framing error), two `Z9IO_FLAG`s are prepended
 */
void Z9IO_device_recv(struct z9io_device *, kcb_t *, uint16_t *crc, struct k_work *rx_return, unsigned msec);

/**
 * @brief Function to disable receiver
 * 
 * Returns true if receiver was active
 * 
 */
bool Z9IO_device_recv_disable(struct z9io_device *);

// link level flag
#define Z9IO_FLAG   0x7f

#ifdef __cplusplus
}
#endif
```

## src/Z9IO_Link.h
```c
#pragma once


#include "Z9IO_Device.h"
#include "Z9Crypto.h"

#include "KernelCharacterBuffer.h"

#include <zephyr/kernel.h>
#include <zephyr/sys/slist.h>

#include <array>
#include <stdint.h>

#define NUM_Z9IO_LINK 2

// declare signature of inbound method
struct Z9IO_Link;
using Z9IO_inbound = void (*)(void *data, Z9IO_Link const&, KCB&);

// declare internal states
enum Z9IO_Link_State : uint8_t {
          LS_INIT
        , LS_WAIT_BOARD_INFO
        , LS_KEY_XCHANGE_PEND
        , LS_KEY_XCHANGE_WAIT
        , LS_IDLE
        , LS_WAIT
        , NUM_Z9IO_Link_State
};

static const char * const Z9IO_Link_State_str [NUM_Z9IO_Link_State] = {
      [LS_INIT]            = "INIT"
    , [LS_WAIT_BOARD_INFO] = "WAIT_INFO"
    , [LS_KEY_XCHANGE_PEND] = "KEY_XCG_PEND"
    , [LS_KEY_XCHANGE_WAIT] = "KEY_XCG_WAIT"
    , [LS_IDLE]             = "IDLE"
    , [LS_WAIT]             = "WAIT"
};

// TBD: KeyStore object
// TBD: Z9IO Protocol Message object
// TBD: CRC16-methods
// TBD: GcmCrypto
// TBD: KCB C-class
// TBD: KernelCharacterBuffer.c, KernelBuffer.c



struct Z9IO_Link
{
//private:
    // controlled lifecycle
    Z9IO_Link(unsigned ordinal, const struct device *);
    //~Z9IO_Link() = delete;

public:
    static Z9IO_Link& get(unsigned ordinal);
    unsigned          unit() const { return _unit; }
    void              xmit(KCB& kcb);
    void              set_inbound(Z9IO_inbound fn, void *data);  

private:
    // workq C-compatible callbacks
    static void xmit_trampoline (struct k_work *cb);
    static void recv_trampoline (struct k_work *cb);

    // C++ workq methods
    void xmit_return   (KCB& kcb);
    bool recv_return   (KCB& kcb);
    void recv_keyexchange(KCB& kcb);

    // implement FSM
    void set_timeout(unsigned msec = 1000);
    void xmit_fsm_loop();

    // ident
    unsigned id() const;
    
    // declare transmit queue
    //kcb_t                *xmit_queue_head;
    //kcb_t               **xmit_queue_tail;
    KCB                 *xmit_kcb, *recv_kcb;

    // device I/O interface
    struct z9io_device   *dev;

    // Inbound interface
    Z9IO_inbound        inbound;
    
    // Zephyr interface objects
    K_WORK_DEFINE      (xmit_work, xmit_trampoline);
    K_WORK_DEFINE      (recv_work, recv_trampoline);
    sys_slist_t         xmit_queue;

    // save the state bytes for last
    uint16_t            xmit_crc, recv_crc;
    uint8_t             seq_number; 
    uint8_t             _unit;
    Z9IO_Link_State     state;
    uint8_t             retry_count;
    
    // define ordinal -> instance mapping for get
    static inline std::array<Z9IO_Link *, NUM_Z9IO_LINK> pInstances;
};

// temp home for support routines
extern uint8_t link_key[16], session_key[16];
// mimic old code
extern uint8_t local_seed[16], gcm_key[16];
extern psa_key_id_t psa_link_key;
```

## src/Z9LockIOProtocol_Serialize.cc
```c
#include "ProtocolMetadata.h"
#include "Z9Serialize.h"
#include "Z9LockIOProtocol_Current_MetaData.h"
#include "init_from_list.h"

#pragama once

namespace z9::protocols::z9lockio
{
using namespace meta;
using namespace z9;
using namespace meta::placeholders;
using namespace kas;
using namespace z9::protocol::z9lockio;


// list of top-level formats
using FORMATS_TYPES = transform<Z9_TYPES, quote<front>>;


struct extract_names
{
    template <typename T>
    using invoke = at_c<T, 1>;
};

using FORMATS_NAMES = transform<Z9_TYPES, extract_names>;


// list of member types
struct extract_member_types
{
    struct get_member_types
    {
        template <typename T>
        using invoke = at_c<T, 3>;
    };

    template <typename T>
    using invoke = transform<at_c<T, 2>, get_member_types>;
};

using MEMBER_TYPES = join<transform<Z9_TYPES, extract_member_types>>;

// find types not previously defined
struct not_in_base
{
    template <typename T>
    using invoke = bool_<!in<FORMATS_TYPES, T>::value>;
};

using INT_TYPES = filter<unique<MEMBER_TYPES>, not_in_base>;
using ALL_DEFNS = concat<Z9_TYPES, INT_TYPES>;
using ALL_TYPES = concat<FORMATS_TYPES, INT_TYPES>;

#if 0
// create type to serialize Z9LockIOProtocols
using Item_t = typename Z9Serialize_struct::SerializeItem;

#if 1
template <typename T, typename NAME, typename MEMBERS>
struct Z9LockIOProtocol_Serialize : Z9Serialize_struct
{
    
    using message_t = T;
    using name      = NAME;
    using members   = init_from_list<Item_t, MEMBERS>;

    void deserialize(reader_t const& reader, uint8_t *dest, width_t width, width_t size) const override
    {
        deserialize_struct(reader, dest, width, NAME(), members::value, members::size);
    }  
};
#endif

using one = front<Z9_TYPES>;
Item_t item { front<at_c<one, 2>>() };
//Z9LockIOProtocol_Serialize<at_c<one,0>, at_c<one, 1>, at_c<one, 2>> first;
#if 1
constexpr auto members = init_from_list<Item_t, at_c<one, 2>>();
constexpr auto _()
{
    static_assert(members.size == at_c<one, 2>::size());
    return members.data;
}
#endif
#endif

template <typename T, typename = void>
struct has_discriminator : std::false_type {};

template <typename T>
struct has_discriminator<T, std::void_t<int_<T::DISCRIMINATOR>>>
        : std::true_type {};

using DISCRIMINATORS_t = filter<FORMATS_TYPES, quote<has_discriminator>>;


struct Z9_TYPE_CTOR
{
    using type = Z9_TYPE_CTOR;

    template <typename T, typename = void>
    using invoke = Z9Serialize_ptr<T>;
};

using Z_t = transform<Z9_TYPES, quote<Z9Serialize_ptr>>::type;
using ZZZZ = init_from_list<Z9Serialize_base const *, Z_t>;
constexpr auto ZZZZ_value = init_from_list<Z9Serialize_base const *, Z_t>::value;
//using Z_t = init_from_list<Z9Serialize_base const *, Z9_TYPES, quote<Z9Serialize_ptr>>;

// generate list of formatters
//using ZZZZ = init_from_list<Z9Serialize_base const *, FORMATS, Z9_TYPE_CTOR>;

//constexpr auto ZZZZ = init_from_list<Z9Serialize_base const *, Z_t>();
//constexpr auto ZZZZ_size  = init_from_list<Z9Serialize_base const *, Z_t>::size;
//using ZZZZ = init_from_list<Z9Serialize_base const *, Z9_TYPES, Z9_TYPE_CTOR>;

//using ZZZZ = init_from_list<Z9Serialize_base const *, transform<Z9_TYPES, quote<Z9Serialize_ptr>>>;

template <typename T>
constexpr const Z9Serialize_base *getFormatter()
{
    static_assert(ZZZZ::size == 75);
    //static_assert(INT_TYPES::size() == 4);
    //static_assert(DISCRIMINATORS_t::size() == 46);

    using N = meta::find_index<FORMATS_TYPES, T>;

    //return formatters[N::value];
    //return ZZZZ.data[n];
    //return ZZZZ.data[N::value];
    //return ZZZZ().value[N::value];
    return ZZZZ_value[N::value];
    return {};

}

}
```
